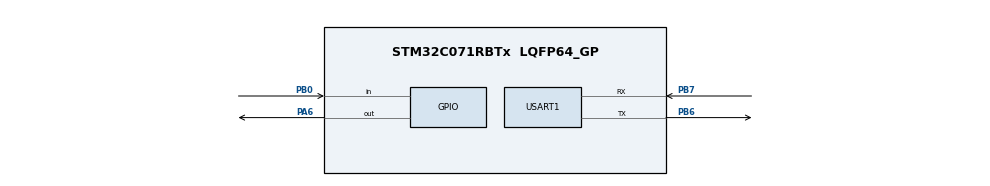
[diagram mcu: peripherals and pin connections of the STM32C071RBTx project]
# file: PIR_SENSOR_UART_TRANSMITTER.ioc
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Dma.Request0=USART1_TX
Dma.USART1_TX.0.Direction=DMA_MEMORY_TO_PERIPH
Dma.USART1_TX.0.EventEnable=DISABLE
Dma.USART1_TX.0.Instance=DMA1_Channel1
Dma.USART1_TX.0.MemDataAlignment=DMA_MDATAALIGN_BYTE
Dma.USART1_TX.0.MemInc=DMA_MINC_ENABLE
Dma.USART1_TX.0.Mode=DMA_NORMAL
Dma.USART1_TX.0.PeriphDataAlignment=DMA_PDATAALIGN_BYTE
Dma.USART1_TX.0.PeriphInc=DMA_PINC_DISABLE
Dma.USART1_TX.0.Polarity=HAL_DMAMUX_REQ_GEN_RISING
Dma.USART1_TX.0.Priority=DMA_PRIORITY_LOW
Dma.USART1_TX.0.RequestNumber=1
Dma.USART1_TX.0.SignalID=NONE
Dma.USART1_TX.0.SyncEnable=DISABLE
Dma.USART1_TX.0.SyncPolarity=HAL_DMAMUX_SYNC_NO_EVENT
Dma.USART1_TX.0.SyncRequestNumber=1
Dma.USART1_TX.0.SyncSignalID=NONE
Mcu.Family=STM32C0
Mcu.Name=STM32C071RBTx
Mcu.Package=LQFP64_GP
NVIC.DMA1_Channel1_IRQn=true\:0\:0\:false\:false\:true\:false\:true\:true
NVIC.USART1_IRQn=true\:0\:0\:false\:false\:true\:true\:true\:true
PA6.Signal=GPIO_Output
PB0.Signal=GPIO_Input
PB6.Mode=Asynchronous
PB6.Signal=USART1_TX
PB7.Mode=Asynchronous
PB7.Signal=USART1_RX
ProjectManager.HeapSize=0x200
ProjectManager.StackSize=0x400
ProjectManager.TargetToolchain=CMake
RCC.ADCFreq_Value=48000000
RCC.AHBFreq_Value=48000000
RCC.CortexFreq_Value=48000000
RCC.EXTERNAL_CLOCK_VALUE=12288000
RCC.HCLKFreq_Value=48000000
RCC.HSE_VALUE=8000000
RCC.HSI48_VALUE=48000000
RCC.HSISYSCLKDivider=RCC_HSI_DIV1
RCC.HSI_VALUE=48000000
RCC.LSE_VALUE=32768
RCC.SYSCLKFreq_VALUE=48000000
TIM3.Prescaler=47
USART1.VirtualMode-Asynchronous=VM_ASYNC
VP_TIM3_VS_ClockSourceINT.Mode=Internal
board=custom

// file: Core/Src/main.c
/* USER CODE BEGIN Header */
/**
  ******************************************************************************
  * @file           : main.c
  * @brief          : Main program body
  ******************************************************************************
  * @attention
  *
  * Copyright (c) 2026 STMicroelectronics.
  * All rights reserved.
  *
  * This software is licensed under terms that can be found in the LICENSE file
  * in the root directory of this software component.
  * If no LICENSE file comes with this software, it is provided AS-IS.
  *
  ******************************************************************************
  */
/* USER CODE END Header */
#include "main.h"

/* USER CODE BEGIN Includes */

#include "../Inc/delay.h"
#include "../Inc/pir.h"
#include "../Inc/uartTx.h"
#include "../Inc/dispatcher.h"

/* USER CODE END Includes */

TIM_HandleTypeDef htim3;

UART_HandleTypeDef huart1;
DMA_HandleTypeDef hdma_usart1_tx;

void SystemClock_Config(void);
static void MX_GPIO_Init(void);
static void MX_DMA_Init(void);
static void MX_TIM3_Init(void);
static void MX_USART1_UART_Init(void);

int main(void)
{

  /* MCU Configuration--------------------------------------------------------*/

  /* Reset of all peripherals, Initializes the Flash interface and the Systick. */
  HAL_Init();

  /* Configure the system clock */
  SystemClock_Config();

  /* Initialize all configured peripherals */
  MX_GPIO_Init();
  MX_DMA_Init();
  MX_TIM3_Init();
  MX_USART1_UART_Init();
  /* USER CODE BEGIN 2 */

  delayInit(&htim3);
  pirInit();
  uartTxInit(&huart1);

  /* USER CODE END 2 */

  /* Infinite loop */
  while (1)
  {

    /* USER CODE BEGIN 3 */

    dispatcher();
  }
  /* USER CODE END 3 */
}

void SystemClock_Config(void)
{
  RCC_OscInitTypeDef RCC_OscInitStruct = {0};
  RCC_ClkInitTypeDef RCC_ClkInitStruct = {0};

  __HAL_FLASH_SET_LATENCY(FLASH_LATENCY_1);

  /** Initializes the RCC Oscillators according to the specified parameters
  * in the RCC_OscInitTypeDef structure.
  */
  RCC_OscInitStruct.OscillatorType = RCC_OSCILLATORTYPE_HSI;
  RCC_OscInitStruct.HSIState = RCC_HSI_ON;
  RCC_OscInitStruct.HSIDiv = RCC_HSI_DIV1;
  RCC_OscInitStruct.HSICalibrationValue = RCC_HSICALIBRATION_DEFAULT;
  if (HAL_RCC_OscConfig(&RCC_OscInitStruct) != HAL_OK)
  {
    Error_Handler();
  }

  /** Initializes the CPU, AHB and APB buses clocks
  */
  RCC_ClkInitStruct.ClockType = RCC_CLOCKTYPE_HCLK|RCC_CLOCKTYPE_SYSCLK
                              |RCC_CLOCKTYPE_PCLK1;
  RCC_ClkInitStruct.SYSCLKSource = RCC_SYSCLKSOURCE_HSI;
  RCC_ClkInitStruct.SYSCLKDivider = RCC_SYSCLK_DIV1;
  RCC_ClkInitStruct.AHBCLKDivider = RCC_HCLK_DIV1;
  RCC_ClkInitStruct.APB1CLKDivider = RCC_APB1_DIV1;

  if (HAL_RCC_ClockConfig(&RCC_ClkInitStruct, FLASH_LATENCY_1) != HAL_OK)
  {
    Error_Handler();
  }
}

static void MX_TIM3_Init(void)
{

  TIM_ClockConfigTypeDef sClockSourceConfig = {0};
  TIM_MasterConfigTypeDef sMasterConfig = {0};

  htim3.Instance = TIM3;
  htim3.Init.Prescaler = 47;
  htim3.Init.CounterMode = TIM_COUNTERMODE_UP;
  htim3.Init.Period = 65535;
  htim3.Init.ClockDivision = TIM_CLOCKDIVISION_DIV1;
  htim3.Init.AutoReloadPreload = TIM_AUTORELOAD_PRELOAD_DISABLE;
  if (HAL_TIM_Base_Init(&htim3) != HAL_OK)
  {
    Error_Handler();
  }
  sClockSourceConfig.ClockSource = TIM_CLOCKSOURCE_INTERNAL;
  if (HAL_TIM_ConfigClockSource(&htim3, &sClockSourceConfig) != HAL_OK)
  {
    Error_Handler();
  }
  sMasterConfig.MasterOutputTrigger = TIM_TRGO_RESET;
  sMasterConfig.MasterSlaveMode = TIM_MASTERSLAVEMODE_DISABLE;
  if (HAL_TIMEx_MasterConfigSynchronization(&htim3, &sMasterConfig) != HAL_OK)
  {
    Error_Handler();
  }

}

static void MX_USART1_UART_Init(void)
{

  huart1.Instance = USART1;
  huart1.Init.BaudRate = 115200;
  huart1.Init.WordLength = UART_WORDLENGTH_8B;
  huart1.Init.StopBits = UART_STOPBITS_1;
  huart1.Init.Parity = UART_PARITY_NONE;
  huart1.Init.Mode = UART_MODE_TX_RX;
  huart1.Init.HwFlowCtl = UART_HWCONTROL_NONE;
  huart1.Init.OverSampling = UART_OVERSAMPLING_16;
  huart1.Init.OneBitSampling = UART_ONE_BIT_SAMPLE_DISABLE;
  huart1.Init.ClockPrescaler = UART_PRESCALER_DIV1;
  huart1.AdvancedInit.AdvFeatureInit = UART_ADVFEATURE_NO_INIT;
  if (HAL_UART_Init(&huart1) != HAL_OK)
  {
    Error_Handler();
  }
  if (HAL_UARTEx_SetTxFifoThreshold(&huart1, UART_TXFIFO_THRESHOLD_1_8) != HAL_OK)
  {
    Error_Handler();
  }
  if (HAL_UARTEx_SetRxFifoThreshold(&huart1, UART_RXFIFO_THRESHOLD_1_8) != HAL_OK)
  {
    Error_Handler();
  }
  if (HAL_UARTEx_DisableFifoMode(&huart1) != HAL_OK)
  {
    Error_Handler();
  }

}

static void MX_DMA_Init(void)
{

  /* DMA controller clock enable */
  __HAL_RCC_DMA1_CLK_ENABLE();

  /* DMA interrupt init */
  /* DMA1_Channel1_IRQn interrupt configuration */
  HAL_NVIC_SetPriority(DMA1_Channel1_IRQn, 0, 0);
  HAL_NVIC_EnableIRQ(DMA1_Channel1_IRQn);

}

static void MX_GPIO_Init(void)
{
  GPIO_InitTypeDef GPIO_InitStruct = {0};

  /* GPIO Ports Clock Enable */
  __HAL_RCC_GPIOA_CLK_ENABLE();
  __HAL_RCC_GPIOB_CLK_ENABLE();

  /*Configure GPIO pin Output Level */
  HAL_GPIO_WritePin(GPIOA, GPIO_PIN_6, GPIO_PIN_RESET);

  /*Configure GPIO pin : PA6 */
  GPIO_InitStruct.Pin = GPIO_PIN_6;
  GPIO_InitStruct.Mode = GPIO_MODE_OUTPUT_PP;
  GPIO_InitStruct.Pull = GPIO_NOPULL;
  GPIO_InitStruct.Speed = GPIO_SPEED_FREQ_LOW;
  HAL_GPIO_Init(GPIOA, &GPIO_InitStruct);

  /*Configure GPIO pin : PB0 */
  GPIO_InitStruct.Pin = GPIO_PIN_0;
  GPIO_InitStruct.Mode = GPIO_MODE_INPUT;
  GPIO_InitStruct.Pull = GPIO_NOPULL;
  HAL_GPIO_Init(GPIOB, &GPIO_InitStruct);

}

void Error_Handler(void)
{
  __disable_irq();
  while (1)
  {
  }
}
